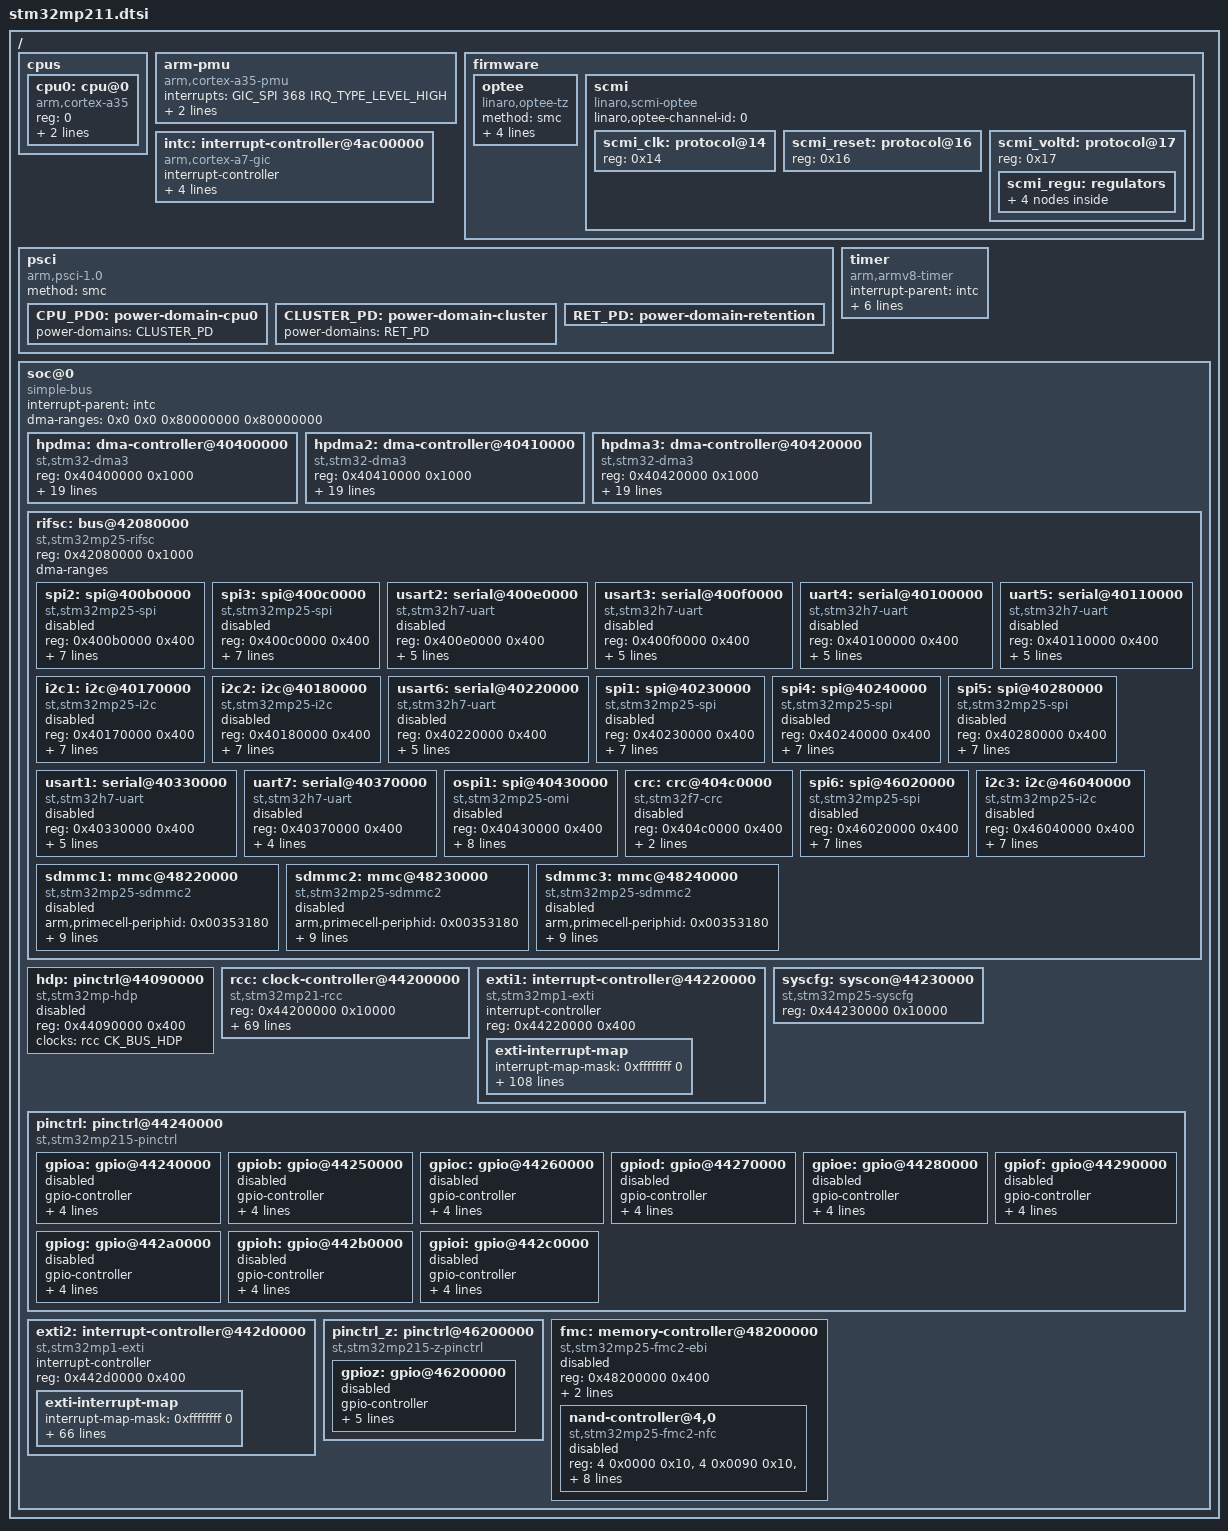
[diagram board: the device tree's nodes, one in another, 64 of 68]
// SPDX-License-Identifier: (GPL-2.0-only OR BSD-3-Clause)
/*
 * Copyright (C) STMicroelectronics 2024 - All Rights Reserved
 * Author: Alexandre Torgue <alexandre.torgue@foss.st.com> for STMicroelectronics.
 */
#include <dt-bindings/clock/st,stm32mp21-rcc.h>
#include <dt-bindings/interrupt-controller/arm-gic.h>
#include <dt-bindings/reset/st,stm32mp21-rcc.h>
#include <dt-bindings/regulator/st,stm32mp21-regulator.h>

/ {
	#address-cells = <2>;
	#size-cells = <2>;

	cpus {
		#address-cells = <1>;
		#size-cells = <0>;

		cpu0: cpu@0 {
			compatible = "arm,cortex-a35";
			device_type = "cpu";
			reg = <0>;
			enable-method = "psci";
			power-domains = <&CPU_PD0>;
			power-domain-names = "psci";
		};
	};

	arm-pmu {
		compatible = "arm,cortex-a35-pmu";
		interrupts = <GIC_SPI 368 IRQ_TYPE_LEVEL_HIGH>;
		interrupt-affinity = <&cpu0>;
		interrupt-parent = <&intc>;
	};

	firmware {
		optee {
			compatible = "linaro,optee-tz";
			method = "smc";
			interrupt-parent = <&intc>;
			interrupts = <GIC_PPI 15 (GIC_CPU_MASK_SIMPLE(1) | IRQ_TYPE_LEVEL_LOW)>;
			interrupt-controller;
			#interrupt-cells = <1>;
		};

		scmi: scmi {
			compatible = "linaro,scmi-optee";
			#address-cells = <1>;
			#size-cells = <0>;
			linaro,optee-channel-id = <0>;

			scmi_clk: protocol@14 {
				reg = <0x14>;
				#clock-cells = <1>;
			};

			scmi_reset: protocol@16 {
				reg = <0x16>;
				#reset-cells = <1>;
			};

			scmi_voltd: protocol@17 {
				reg = <0x17>;

				scmi_regu: regulators {
					#address-cells = <1>;
					#size-cells = <0>;

					scmi_vddio1: regulator@0 {
						reg = <VOLTD_SCMI_VDDIO1>;
						regulator-name = "vddio1";
					};
					scmi_vddio2: regulator@1 {
						reg = <VOLTD_SCMI_VDDIO2>;
						regulator-name = "vddio2";
					};
					scmi_vddio3: regulator@2 {
						reg = <VOLTD_SCMI_VDDIO3>;
						regulator-name = "vddio3";
					};
					scmi_vdda18adc: regulator@7 {
						reg = <VOLTD_SCMI_ADC>;
						regulator-name = "vdda18adc";
					};
				};
			};
		};
	};

	intc: interrupt-controller@4ac00000 {
		compatible = "arm,cortex-a7-gic";
		#interrupt-cells = <3>;
		interrupt-controller;
		reg = <0x0 0x4ac10000 0x0 0x1000>,
		      <0x0 0x4ac20000 0x0 0x2000>,
		      <0x0 0x4ac40000 0x0 0x2000>,
		      <0x0 0x4ac60000 0x0 0x2000>;
	};

	psci {
		compatible = "arm,psci-1.0";
		method = "smc";

		CPU_PD0: power-domain-cpu0 {
			#power-domain-cells = <0>;
			power-domains = <&CLUSTER_PD>;
		};

		CLUSTER_PD: power-domain-cluster {
			#power-domain-cells = <0>;
			power-domains = <&RET_PD>;
		};

		RET_PD: power-domain-retention {
			#power-domain-cells = <0>;
		};
	};

	timer {
		compatible = "arm,armv8-timer";
		interrupt-parent = <&intc>;
		interrupts = <GIC_PPI 13 (GIC_CPU_MASK_SIMPLE(1) | IRQ_TYPE_LEVEL_LOW)>,
			     <GIC_PPI 14 (GIC_CPU_MASK_SIMPLE(1) | IRQ_TYPE_LEVEL_LOW)>,
			     <GIC_PPI 11 (GIC_CPU_MASK_SIMPLE(1) | IRQ_TYPE_LEVEL_LOW)>,
			     <GIC_PPI 10 (GIC_CPU_MASK_SIMPLE(1) | IRQ_TYPE_LEVEL_LOW)>;
		arm,no-tick-in-suspend;
	};

	soc@0 {
		compatible = "simple-bus";
		#address-cells = <1>;
		#size-cells = <1>;
		interrupt-parent = <&intc>;
		ranges = <0x0 0x0 0x0 0x80000000>;
		dma-ranges = <0x0 0x0 0x80000000 0x80000000>;

		hpdma: dma-controller@40400000 {
			compatible = "st,stm32-dma3";
			reg = <0x40400000 0x1000>;
			interrupts = <GIC_SPI 31 IRQ_TYPE_LEVEL_HIGH>,
				     <GIC_SPI 32 IRQ_TYPE_LEVEL_HIGH>,
				     <GIC_SPI 33 IRQ_TYPE_LEVEL_HIGH>,
				     <GIC_SPI 34 IRQ_TYPE_LEVEL_HIGH>,
				     <GIC_SPI 35 IRQ_TYPE_LEVEL_HIGH>,
				     <GIC_SPI 36 IRQ_TYPE_LEVEL_HIGH>,
				     <GIC_SPI 37 IRQ_TYPE_LEVEL_HIGH>,
				     <GIC_SPI 38 IRQ_TYPE_LEVEL_HIGH>,
				     <GIC_SPI 39 IRQ_TYPE_LEVEL_HIGH>,
				     <GIC_SPI 40 IRQ_TYPE_LEVEL_HIGH>,
				     <GIC_SPI 41 IRQ_TYPE_LEVEL_HIGH>,
				     <GIC_SPI 42 IRQ_TYPE_LEVEL_HIGH>,
				     <GIC_SPI 43 IRQ_TYPE_LEVEL_HIGH>,
				     <GIC_SPI 44 IRQ_TYPE_LEVEL_HIGH>,
				     <GIC_SPI 45 IRQ_TYPE_LEVEL_HIGH>,
				     <GIC_SPI 46 IRQ_TYPE_LEVEL_HIGH>;
			clocks = <&scmi_clk CK_SCMI_HPDMA1>;
			#dma-cells = <3>;
			st,axi-max-burst-len = <16>;
			st,syscfg-arcr = <&syscfg 0x2050 0x1>;
		};

		hpdma2: dma-controller@40410000 {
			compatible = "st,stm32-dma3";
			reg = <0x40410000 0x1000>;
			interrupts = <GIC_SPI 47 IRQ_TYPE_LEVEL_HIGH>,
				     <GIC_SPI 48 IRQ_TYPE_LEVEL_HIGH>,
				     <GIC_SPI 49 IRQ_TYPE_LEVEL_HIGH>,
				     <GIC_SPI 50 IRQ_TYPE_LEVEL_HIGH>,
				     <GIC_SPI 51 IRQ_TYPE_LEVEL_HIGH>,
				     <GIC_SPI 52 IRQ_TYPE_LEVEL_HIGH>,
				     <GIC_SPI 53 IRQ_TYPE_LEVEL_HIGH>,
				     <GIC_SPI 54 IRQ_TYPE_LEVEL_HIGH>,
				     <GIC_SPI 55 IRQ_TYPE_LEVEL_HIGH>,
				     <GIC_SPI 56 IRQ_TYPE_LEVEL_HIGH>,
				     <GIC_SPI 57 IRQ_TYPE_LEVEL_HIGH>,
				     <GIC_SPI 58 IRQ_TYPE_LEVEL_HIGH>,
				     <GIC_SPI 59 IRQ_TYPE_LEVEL_HIGH>,
				     <GIC_SPI 60 IRQ_TYPE_LEVEL_HIGH>,
				     <GIC_SPI 61 IRQ_TYPE_LEVEL_HIGH>,
				     <GIC_SPI 62 IRQ_TYPE_LEVEL_HIGH>;
			clocks = <&scmi_clk CK_SCMI_HPDMA2>;
			#dma-cells = <3>;
			st,axi-max-burst-len = <16>;
			st,syscfg-arcr = <&syscfg 0x2050 0x2>;
		};

		hpdma3: dma-controller@40420000 {
			compatible = "st,stm32-dma3";
			reg = <0x40420000 0x1000>;
			interrupts = <GIC_SPI 63 IRQ_TYPE_LEVEL_HIGH>,
				     <GIC_SPI 64 IRQ_TYPE_LEVEL_HIGH>,
				     <GIC_SPI 65 IRQ_TYPE_LEVEL_HIGH>,
				     <GIC_SPI 66 IRQ_TYPE_LEVEL_HIGH>,
				     <GIC_SPI 67 IRQ_TYPE_LEVEL_HIGH>,
				     <GIC_SPI 68 IRQ_TYPE_LEVEL_HIGH>,
				     <GIC_SPI 69 IRQ_TYPE_LEVEL_HIGH>,
				     <GIC_SPI 70 IRQ_TYPE_LEVEL_HIGH>,
				     <GIC_SPI 71 IRQ_TYPE_LEVEL_HIGH>,
				     <GIC_SPI 72 IRQ_TYPE_LEVEL_HIGH>,
				     <GIC_SPI 73 IRQ_TYPE_LEVEL_HIGH>,
				     <GIC_SPI 74 IRQ_TYPE_LEVEL_HIGH>,
				     <GIC_SPI 75 IRQ_TYPE_LEVEL_HIGH>,
				     <GIC_SPI 76 IRQ_TYPE_LEVEL_HIGH>,
				     <GIC_SPI 77 IRQ_TYPE_LEVEL_HIGH>,
				     <GIC_SPI 78 IRQ_TYPE_LEVEL_HIGH>;
			clocks = <&scmi_clk CK_SCMI_HPDMA3>;
			#dma-cells = <3>;
			st,axi-max-burst-len = <16>;
			st,syscfg-arcr = <&syscfg 0x2050 0x4>;
		};

		rifsc: bus@42080000 {
			compatible = "st,stm32mp25-rifsc", "simple-bus";
			reg = <0x42080000 0x1000>;
			#address-cells = <1>;
			#size-cells = <1>;
			#access-controller-cells = <1>;
			ranges;
			dma-ranges;

			spi2: spi@400b0000 {
				#address-cells = <1>;
				#size-cells = <0>;
				compatible = "st,stm32mp25-spi";
				reg = <0x400b0000 0x400>;
				interrupts = <GIC_SPI 100 IRQ_TYPE_LEVEL_HIGH>;
				clocks = <&rcc CK_KER_SPI2>;
				resets = <&rcc SPI2_R>;
				dmas = <&hpdma 34 0x40 0x3012>,
				       <&hpdma 35 0x40 0x3021>;
				dma-names = "rx", "tx";
				access-controllers = <&rifsc 23>;
				power-domains = <&CLUSTER_PD>;
				status = "disabled";
			};

			spi3: spi@400c0000 {
				#address-cells = <1>;
				#size-cells = <0>;
				compatible = "st,stm32mp25-spi";
				reg = <0x400c0000 0x400>;
				interrupts = <GIC_SPI 112 IRQ_TYPE_LEVEL_HIGH>;
				clocks = <&rcc CK_KER_SPI3>;
				resets = <&rcc SPI3_R>;
				dmas = <&hpdma 36 0x40 0x3012>,
				       <&hpdma 37 0x40 0x3021>;
				dma-names = "rx", "tx";
				access-controllers = <&rifsc 24>;
				power-domains = <&CLUSTER_PD>;
				status = "disabled";
			};

			usart2: serial@400e0000 {
				compatible = "st,stm32h7-uart";
				reg = <0x400e0000 0x400>;
				interrupts = <GIC_SPI 102 IRQ_TYPE_LEVEL_HIGH>;
				clocks = <&rcc CK_KER_USART2>;
				dmas = <&hpdma 11 0x40 0x12>,
				       <&hpdma 12 0x40 0x3021>;
				dma-names = "rx", "tx";
				access-controllers = <&rifsc 32>;
				power-domains = <&CLUSTER_PD>;
				status = "disabled";
			};

			usart3: serial@400f0000 {
				compatible = "st,stm32h7-uart";
				reg = <0x400f0000 0x400>;
				interrupts = <GIC_SPI 103 IRQ_TYPE_LEVEL_HIGH>;
				clocks = <&rcc CK_KER_USART3>;
				dmas = <&hpdma 13 0x40 0x12>,
				       <&hpdma 14 0x40 0x3021>;
				dma-names = "rx", "tx";
				access-controllers = <&rifsc 33>;
				power-domains = <&CLUSTER_PD>;
				status = "disabled";
			};

			uart4: serial@40100000 {
				compatible = "st,stm32h7-uart";
				reg = <0x40100000 0x400>;
				interrupts = <GIC_SPI 113 IRQ_TYPE_LEVEL_HIGH>;
				clocks = <&rcc CK_KER_UART4>;
				dmas = <&hpdma 15 0x40 0x12>,
				       <&hpdma 16 0x40 0x3021>;
				dma-names = "rx", "tx";
				access-controllers = <&rifsc 34>;
				power-domains = <&CLUSTER_PD>;
				status = "disabled";
			};

			uart5: serial@40110000 {
				compatible = "st,stm32h7-uart";
				reg = <0x40110000 0x400>;
				interrupts = <GIC_SPI 114 IRQ_TYPE_LEVEL_HIGH>;
				clocks = <&rcc CK_KER_UART5>;
				dmas = <&hpdma 17 0x40 0x12>,
				       <&hpdma 18 0x40 0x3021>;
				dma-names = "rx", "tx";
				access-controllers = <&rifsc 35>;
				power-domains = <&CLUSTER_PD>;
				status = "disabled";
			};

			i2c1: i2c@40170000 {
				compatible = "st,stm32mp25-i2c";
				reg = <0x40170000 0x400>;
				interrupt-names = "event";
				interrupts = <GIC_SPI 95 IRQ_TYPE_LEVEL_HIGH>;
				clocks = <&rcc CK_KER_I2C1>;
				resets = <&rcc I2C1_R>;
				#address-cells = <1>;
				#size-cells = <0>;
				dmas = <&hpdma 23 0x40 0x3012>,
				       <&hpdma 24 0x40 0x3021>;
				dma-names = "rx", "tx";
				access-controllers = <&rifsc 41>;
				power-domains = <&CLUSTER_PD>;
				status = "disabled";
			};

			i2c2: i2c@40180000 {
				compatible = "st,stm32mp25-i2c";
				reg = <0x40180000 0x400>;
				interrupt-names = "event";
				interrupts = <GIC_SPI 97 IRQ_TYPE_LEVEL_HIGH>;
				clocks = <&rcc CK_KER_I2C2>;
				resets = <&rcc I2C2_R>;
				#address-cells = <1>;
				#size-cells = <0>;
				dmas = <&hpdma 26 0x40 0x3012>,
				       <&hpdma 27 0x40 0x3021>;
				dma-names = "rx", "tx";
				access-controllers = <&rifsc 42>;
				power-domains = <&CLUSTER_PD>;
				status = "disabled";
			};

			usart6: serial@40220000 {
				compatible = "st,stm32h7-uart";
				reg = <0x40220000 0x400>;
				interrupts = <GIC_SPI 123 IRQ_TYPE_LEVEL_HIGH>;
				clocks = <&rcc CK_KER_USART6>;
				dmas = <&hpdma 19 0x40 0x12>,
				       <&hpdma 20 0x40 0x3021>;
				dma-names = "rx", "tx";
				access-controllers = <&rifsc 36>;
				power-domains = <&CLUSTER_PD>;
				status = "disabled";
			};

			spi1: spi@40230000 {
				#address-cells = <1>;
				#size-cells = <0>;
				compatible = "st,stm32mp25-spi";
				reg = <0x40230000 0x400>;
				interrupts = <GIC_SPI 99 IRQ_TYPE_LEVEL_HIGH>;
				clocks = <&rcc CK_KER_SPI1>;
				resets = <&rcc SPI1_R>;
				dmas = <&hpdma 32 0x40 0x3012>,
				       <&hpdma 33 0x40 0x3021>;
				dma-names = "rx", "tx";
				access-controllers = <&rifsc 22>;
				power-domains = <&CLUSTER_PD>;
				status = "disabled";
			};

			spi4: spi@40240000 {
				#address-cells = <1>;
				#size-cells = <0>;
				compatible = "st,stm32mp25-spi";
				reg = <0x40240000 0x400>;
				interrupts = <GIC_SPI 137 IRQ_TYPE_LEVEL_HIGH>;
				clocks = <&rcc CK_KER_SPI4>;
				resets = <&rcc SPI4_R>;
				dmas = <&hpdma 38 0x40 0x3012>,
				       <&hpdma 39 0x40 0x3021>;
				dma-names = "rx", "tx";
				access-controllers = <&rifsc 25>;
				power-domains = <&CLUSTER_PD>;
				status = "disabled";
			};

			spi5: spi@40280000 {
				#address-cells = <1>;
				#size-cells = <0>;
				compatible = "st,stm32mp25-spi";
				reg = <0x40280000 0x400>;
				interrupts = <GIC_SPI 138 IRQ_TYPE_LEVEL_HIGH>;
				clocks = <&rcc CK_KER_SPI5>;
				resets = <&rcc SPI5_R>;
				dmas = <&hpdma 40 0x40 0x3012>,
				       <&hpdma 41 0x40 0x3021>;
				dma-names = "rx", "tx";
				access-controllers = <&rifsc 26>;
				power-domains = <&CLUSTER_PD>;
				status = "disabled";
			};

			usart1: serial@40330000 {
				compatible = "st,stm32h7-uart";
				reg = <0x40330000 0x400>;
				interrupts = <GIC_SPI 101 IRQ_TYPE_LEVEL_HIGH>;
				clocks = <&rcc CK_KER_USART1>;
				dmas = <&hpdma 9 0x40 0x12>,
				       <&hpdma 10 0x40 0x3021>;
				dma-names = "rx", "tx";
				access-controllers = <&rifsc 31>;
				power-domains = <&CLUSTER_PD>;
				status = "disabled";
			};

			uart7: serial@40370000 {
				compatible = "st,stm32h7-uart";
				reg = <0x40370000 0x400>;
				interrupts = <GIC_SPI 135 IRQ_TYPE_LEVEL_HIGH>;
				clocks = <&rcc CK_KER_UART7>;
				dmas = <&hpdma 21 0x40 0x12>,
				       <&hpdma 22 0x40 0x3021>;
				dma-names = "rx", "tx";
				access-controllers = <&rifsc 37>;
				status = "disabled";
			};

			ospi1: spi@40430000 {
				compatible = "st,stm32mp25-omi";
				reg = <0x40430000 0x400>;
				interrupts = <GIC_SPI 146 IRQ_TYPE_LEVEL_HIGH>;
				dmas = <&hpdma 2 0x62 0x00003121>,
				       <&hpdma 2 0x42 0x00003112>;
				dma-names = "tx", "rx";
				st,syscfg-dlyb = <&syscfg 0x1000>;
				clocks = <&scmi_clk CK_SCMI_OSPI1>;
				resets = <&scmi_reset RST_SCMI_OSPI1>, <&scmi_reset RST_SCMI_OSPI1DLL>;
				access-controllers = <&rifsc 74>;
				status = "disabled";
			};

			crc: crc@404c0000 {
				compatible = "st,stm32f7-crc";
				reg = <0x404c0000 0x400>;
				clocks = <&rcc CK_BUS_CRC>;
				access-controllers = <&rifsc 109>;
				status = "disabled";
			};

			spi6: spi@46020000 {
				#address-cells = <1>;
				#size-cells = <0>;
				compatible = "st,stm32mp25-spi";
				reg = <0x46020000 0x400>;
				interrupts = <GIC_SPI 139 IRQ_TYPE_LEVEL_HIGH>;
				clocks = <&rcc CK_KER_SPI6>;
				resets = <&rcc SPI6_R>;
				dmas = <&hpdma 42 0x40 0x3012>,
				       <&hpdma 43 0x40 0x3021>;
				dma-names = "rx", "tx";
				access-controllers = <&rifsc 27>;
				power-domains = <&CLUSTER_PD>;
				status = "disabled";
			};

			i2c3: i2c@46040000 {
				compatible = "st,stm32mp25-i2c";
				reg = <0x46040000 0x400>;
				interrupt-names = "event";
				interrupts = <GIC_SPI 137 IRQ_TYPE_LEVEL_HIGH>;
				clocks = <&rcc CK_KER_I2C3>;
				resets = <&rcc I2C3_R>;
				#address-cells = <1>;
				#size-cells = <0>;
				dmas = <&hpdma 29 0x40 0x3012>,
				       <&hpdma 30 0x40 0x3021>;
				dma-names = "rx", "tx";
				access-controllers = <&rifsc 43>;
				power-domains = <&CLUSTER_PD>;
				status = "disabled";
			};

			sdmmc1: mmc@48220000 {
				compatible = "st,stm32mp25-sdmmc2", "arm,pl18x", "arm,primecell";
				arm,primecell-periphid = <0x00353180>;
				reg = <0x48220000 0x400>, <0x44230400 0x8>;
				interrupts = <GIC_SPI 110 IRQ_TYPE_LEVEL_HIGH>;
				clocks = <&rcc CK_KER_SDMMC1>;
				clock-names = "apb_pclk";
				resets = <&rcc SDMMC1_R>;
				cap-sd-highspeed;
				cap-mmc-highspeed;
				max-frequency = <120000000>;
				access-controllers = <&rifsc 76>;
				st,syscfg-arcr = <&syscfg 0x40c 0x1>;
				status = "disabled";
			};

			sdmmc2: mmc@48230000 {
				compatible = "st,stm32mp25-sdmmc2", "arm,pl18x", "arm,primecell";
				arm,primecell-periphid = <0x00353180>;
				reg = <0x48230000 0x400>, <0x44230800 0x8>;
				interrupts = <GIC_SPI 169 IRQ_TYPE_LEVEL_HIGH>;
				clocks = <&rcc CK_KER_SDMMC2>;
				clock-names = "apb_pclk";
				resets = <&rcc SDMMC2_R>;
				cap-sd-highspeed;
				cap-mmc-highspeed;
				max-frequency = <120000000>;
				access-controllers = <&rifsc 77>;
				st,syscfg-arcr = <&syscfg 0x80c 0x1>;
				status = "disabled";
			};

			sdmmc3: mmc@48240000 {
				compatible = "st,stm32mp25-sdmmc2", "arm,pl18x", "arm,primecell";
				arm,primecell-periphid = <0x00353180>;
				reg = <0x48240000 0x400>, <0x44230c00 0x8>;
				interrupts = <GIC_SPI 179 IRQ_TYPE_LEVEL_HIGH>;
				clocks = <&rcc CK_KER_SDMMC3>;
				clock-names = "apb_pclk";
				resets = <&rcc SDMMC3_R>;
				cap-sd-highspeed;
				cap-mmc-highspeed;
				max-frequency = <120000000>;
				access-controllers = <&rifsc 78>;
				st,syscfg-arcr = <&syscfg 0xc0c 0x1>;
				status = "disabled";
			};
		};

		hdp: pinctrl@44090000 {
			compatible = "st,stm32mp-hdp";
			reg = <0x44090000 0x400>;
			clocks = <&rcc CK_BUS_HDP>;
			status = "disabled";
		};

		rcc: clock-controller@44200000 {
			compatible = "st,stm32mp21-rcc";
			reg = <0x44200000 0x10000>;
			#clock-cells = <1>;
			#reset-cells = <1>;
			clocks =
				<&scmi_clk CK_SCMI_HSE>,
				<&scmi_clk CK_SCMI_HSI>,
				<&scmi_clk CK_SCMI_MSI>,
				<&scmi_clk CK_SCMI_LSE>,
				<&scmi_clk CK_SCMI_LSI>,
				<&scmi_clk CK_SCMI_HSE_DIV2>,
				<&scmi_clk CK_SCMI_ICN_HS_MCU>,
				<&scmi_clk CK_SCMI_ICN_LS_MCU>,
				<&scmi_clk CK_SCMI_ICN_SDMMC>,
				<&scmi_clk CK_SCMI_ICN_DDR>,
				<&scmi_clk CK_SCMI_ICN_DISPLAY>,
				<&scmi_clk CK_SCMI_ICN_HSL>,
				<&scmi_clk CK_SCMI_ICN_NIC>,
				<&scmi_clk CK_SCMI_FLEXGEN_07>,
				<&scmi_clk CK_SCMI_FLEXGEN_08>,
				<&scmi_clk CK_SCMI_FLEXGEN_09>,
				<&scmi_clk CK_SCMI_FLEXGEN_10>,
				<&scmi_clk CK_SCMI_FLEXGEN_11>,
				<&scmi_clk CK_SCMI_FLEXGEN_12>,
				<&scmi_clk CK_SCMI_FLEXGEN_13>,
				<&scmi_clk CK_SCMI_FLEXGEN_14>,
				<&scmi_clk CK_SCMI_FLEXGEN_16>,
				<&scmi_clk CK_SCMI_FLEXGEN_17>,
				<&scmi_clk CK_SCMI_FLEXGEN_18>,
				<&scmi_clk CK_SCMI_FLEXGEN_19>,
				<&scmi_clk CK_SCMI_FLEXGEN_20>,
				<&scmi_clk CK_SCMI_FLEXGEN_21>,
				<&scmi_clk CK_SCMI_FLEXGEN_22>,
				<&scmi_clk CK_SCMI_FLEXGEN_23>,
				<&scmi_clk CK_SCMI_FLEXGEN_24>,
				<&scmi_clk CK_SCMI_FLEXGEN_25>,
				<&scmi_clk CK_SCMI_FLEXGEN_26>,
				<&scmi_clk CK_SCMI_FLEXGEN_27>,
				<&scmi_clk CK_SCMI_FLEXGEN_29>,
				<&scmi_clk CK_SCMI_FLEXGEN_30>,
				<&scmi_clk CK_SCMI_FLEXGEN_31>,
				<&scmi_clk CK_SCMI_FLEXGEN_33>,
				<&scmi_clk CK_SCMI_FLEXGEN_36>,
				<&scmi_clk CK_SCMI_FLEXGEN_37>,
				<&scmi_clk CK_SCMI_FLEXGEN_38>,
				<&scmi_clk CK_SCMI_FLEXGEN_39>,
				<&scmi_clk CK_SCMI_FLEXGEN_40>,
				<&scmi_clk CK_SCMI_FLEXGEN_41>,
				<&scmi_clk CK_SCMI_FLEXGEN_42>,
				<&scmi_clk CK_SCMI_FLEXGEN_43>,
				<&scmi_clk CK_SCMI_FLEXGEN_44>,
				<&scmi_clk CK_SCMI_FLEXGEN_45>,
				<&scmi_clk CK_SCMI_FLEXGEN_46>,
				<&scmi_clk CK_SCMI_FLEXGEN_47>,
				<&scmi_clk CK_SCMI_FLEXGEN_48>,
				<&scmi_clk CK_SCMI_FLEXGEN_50>,
				<&scmi_clk CK_SCMI_FLEXGEN_51>,
				<&scmi_clk CK_SCMI_FLEXGEN_52>,
				<&scmi_clk CK_SCMI_FLEXGEN_53>,
				<&scmi_clk CK_SCMI_FLEXGEN_54>,
				<&scmi_clk CK_SCMI_FLEXGEN_55>,
				<&scmi_clk CK_SCMI_FLEXGEN_56>,
				<&scmi_clk CK_SCMI_FLEXGEN_57>,
				<&scmi_clk CK_SCMI_FLEXGEN_58>,
				<&scmi_clk CK_SCMI_FLEXGEN_61>,
				<&scmi_clk CK_SCMI_FLEXGEN_62>,
				<&scmi_clk CK_SCMI_FLEXGEN_63>,
				<&scmi_clk CK_SCMI_ICN_APB1>,
				<&scmi_clk CK_SCMI_ICN_APB2>,
				<&scmi_clk CK_SCMI_ICN_APB3>,
				<&scmi_clk CK_SCMI_ICN_APB4>,
				<&scmi_clk CK_SCMI_ICN_APB5>,
				<&scmi_clk CK_SCMI_ICN_APBDBG>,
				<&scmi_clk CK_SCMI_TIMG1>,
				<&scmi_clk CK_SCMI_TIMG2>;
			access-controllers = <&rifsc 156>;
		};

		exti1: interrupt-controller@44220000 {
			compatible = "st,stm32mp1-exti";
			interrupt-controller;
			#interrupt-cells = <2>;
			#address-cells = <0>;
			reg = <0x44220000 0x400>;
			exti-interrupt-map {
				#address-cells = <0>;
				#interrupt-cells = <2>;
				interrupt-map-mask = <0xffffffff 0>;
				interrupt-map =
					<0  0 &intc 0 0 GIC_SPI 268 IRQ_TYPE_LEVEL_HIGH>,
					<1  0 &intc 0 0 GIC_SPI 269 IRQ_TYPE_LEVEL_HIGH>,
					<2  0 &intc 0 0 GIC_SPI 270 IRQ_TYPE_LEVEL_HIGH>,
					<3  0 &intc 0 0 GIC_SPI 271 IRQ_TYPE_LEVEL_HIGH>,
					<4  0 &intc 0 0 GIC_SPI 272 IRQ_TYPE_LEVEL_HIGH>,
					<5  0 &intc 0 0 GIC_SPI 273 IRQ_TYPE_LEVEL_HIGH>,
					<6  0 &intc 0 0 GIC_SPI 274 IRQ_TYPE_LEVEL_HIGH>,
					<7  0 &intc 0 0 GIC_SPI 275 IRQ_TYPE_LEVEL_HIGH>,
					<8  0 &intc 0 0 GIC_SPI 276 IRQ_TYPE_LEVEL_HIGH>,
					<9  0 &intc 0 0 GIC_SPI 277 IRQ_TYPE_LEVEL_HIGH>,
					<10 0 &intc 0 0 GIC_SPI 278 IRQ_TYPE_LEVEL_HIGH>,
					<11 0 &intc 0 0 GIC_SPI 279 IRQ_TYPE_LEVEL_HIGH>,
					<12 0 &intc 0 0 GIC_SPI 280 IRQ_TYPE_LEVEL_HIGH>,
					<13 0 &intc 0 0 GIC_SPI 281 IRQ_TYPE_LEVEL_HIGH>,
					<14 0 &intc 0 0 GIC_SPI 282 IRQ_TYPE_LEVEL_HIGH>,
					<15 0 &intc 0 0 GIC_SPI 283 IRQ_TYPE_LEVEL_HIGH>,
					<16 0 &intc 0 0 GIC_SPI 0   IRQ_TYPE_LEVEL_HIGH>,
					<17 0 &intc 0 0 GIC_SPI 1   IRQ_TYPE_LEVEL_HIGH>,
					<18 0 &intc 0 0 GIC_SPI 211 IRQ_TYPE_LEVEL_HIGH>,
					<19 0 &intc 0 0 GIC_SPI 210 IRQ_TYPE_LEVEL_HIGH>,
					<21 0 &intc 0 0 GIC_SPI 95  IRQ_TYPE_LEVEL_HIGH>,
					<22 0 &intc 0 0 GIC_SPI 97  IRQ_TYPE_LEVEL_HIGH>,
					<23 0 &intc 0 0 GIC_SPI 124 IRQ_TYPE_LEVEL_HIGH>,
					<26 0 &intc 0 0 GIC_SPI 101 IRQ_TYPE_LEVEL_HIGH>,
					<27 0 &intc 0 0 GIC_SPI 102 IRQ_TYPE_LEVEL_HIGH>,
					<28 0 &intc 0 0 GIC_SPI 103 IRQ_TYPE_LEVEL_HIGH>,
					<29 0 &intc 0 0 GIC_SPI 123 IRQ_TYPE_LEVEL_HIGH>,
					<30 0 &intc 0 0 GIC_SPI 113 IRQ_TYPE_LEVEL_HIGH>,
					<31 0 &intc 0 0 GIC_SPI 114 IRQ_TYPE_LEVEL_HIGH>,
					<32 0 &intc 0 0 GIC_SPI 135 IRQ_TYPE_LEVEL_HIGH>,
					<36 0 &intc 0 0 GIC_SPI 99  IRQ_TYPE_LEVEL_HIGH>,
					<37 0 &intc 0 0 GIC_SPI 100 IRQ_TYPE_LEVEL_HIGH>,
					<38 0 &intc 0 0 GIC_SPI 112 IRQ_TYPE_LEVEL_HIGH>,
					<39 0 &intc 0 0 GIC_SPI 137 IRQ_TYPE_LEVEL_HIGH>,
					<40 0 &intc 0 0 GIC_SPI 138 IRQ_TYPE_LEVEL_HIGH>,
					<41 0 &intc 0 0 GIC_SPI 139 IRQ_TYPE_LEVEL_HIGH>,
					<43 0 &intc 0 0 GIC_SPI 150 IRQ_TYPE_LEVEL_HIGH>,
					<44 0 &intc 0 0 GIC_SPI 158 IRQ_TYPE_LEVEL_HIGH>,
					<47 0 &intc 0 0 GIC_SPI 149 IRQ_TYPE_LEVEL_HIGH>,
					<48 0 &intc 0 0 GIC_SPI 180 IRQ_TYPE_LEVEL_HIGH>,
					<59 0 &intc 0 0 GIC_SPI 152 IRQ_TYPE_LEVEL_HIGH>,
					//	<59 0 &intc 0 0 GIC_SPI 153 IRQ_TYPE_LEVEL_HIGH>,
					<61 0 &intc 0 0 GIC_SPI 154 IRQ_TYPE_LEVEL_HIGH>,
					//	<61 0 &intc 0 0 GIC_SPI 155 IRQ_TYPE_LEVEL_HIGH>,
					<64 0 &intc 0 0 GIC_SPI 185 IRQ_TYPE_LEVEL_HIGH>,
					<67 0 &intc 0 0 GIC_SPI 9   IRQ_TYPE_LEVEL_HIGH>,
					<68 0 &intc 0 0 GIC_SPI 118 IRQ_TYPE_LEVEL_HIGH>,
					<70 0 &intc 0 0 GIC_SPI 121 IRQ_TYPE_LEVEL_HIGH>,
					<72 0 &intc 0 0 GIC_SPI 188 IRQ_TYPE_LEVEL_HIGH>,
					<73 0 &intc 0 0 GIC_SPI 172 IRQ_TYPE_LEVEL_HIGH>,
					<74 0 &intc 0 0 GIC_SPI 96  IRQ_TYPE_LEVEL_HIGH>,
					<75 0 &intc 0 0 GIC_SPI 98  IRQ_TYPE_LEVEL_HIGH>,
					<76 0 &intc 0 0 GIC_SPI 125 IRQ_TYPE_LEVEL_HIGH>,
					<77 0 &intc 0 0 GIC_SPI 205 IRQ_TYPE_LEVEL_HIGH>,
					<78 0 &intc 0 0 GIC_SPI 206 IRQ_TYPE_LEVEL_HIGH>,
					<79 0 &intc 0 0 GIC_SPI 207 IRQ_TYPE_LEVEL_HIGH>;
			};
		};

		syscfg: syscon@44230000 {
			compatible = "st,stm32mp25-syscfg", "syscon";
			reg = <0x44230000 0x10000>;
		};

		pinctrl: pinctrl@44240000 {
			#address-cells = <1>;
			#size-cells = <1>;
			compatible = "st,stm32mp215-pinctrl";
			ranges = <0 0x44240000 0x80400>;

			gpioa: gpio@44240000 {
				gpio-controller;
				#gpio-cells = <2>;
				interrupt-controller;
				#interrupt-cells = <2>;
				reg = <0x0 0x400>;
				clocks = <&scmi_clk CK_SCMI_GPIOA>;
				st,bank-name = "GPIOA";
				status = "disabled";
			};

			gpiob: gpio@44250000 {
				gpio-controller;
				#gpio-cells = <2>;
				interrupt-controller;
				#interrupt-cells = <2>;
				reg = <0x10000 0x400>;
				clocks = <&scmi_clk CK_SCMI_GPIOB>;
				st,bank-name = "GPIOB";
				status = "disabled";
			};

			gpioc: gpio@44260000 {
				gpio-controller;
				#gpio-cells = <2>;
				interrupt-controller;
				#interrupt-cells = <2>;
				reg = <0x20000 0x400>;
				clocks = <&scmi_clk CK_SCMI_GPIOC>;
				st,bank-name = "GPIOC";
				status = "disabled";
			};

			gpiod: gpio@44270000 {
				gpio-controller;
				#gpio-cells = <2>;
				interrupt-controller;
				#interrupt-cells = <2>;
				reg = <0x30000 0x400>;
				clocks = <&scmi_clk CK_SCMI_GPIOD>;
				st,bank-name = "GPIOD";
				status = "disabled";
			};

			gpioe: gpio@44280000 {
				gpio-controller;
				#gpio-cells = <2>;
				interrupt-controller;
				#interrupt-cells = <2>;
				reg = <0x40000 0x400>;
				clocks = <&scmi_clk CK_SCMI_GPIOE>;
				st,bank-name = "GPIOE";
				status = "disabled";
			};

			gpiof: gpio@44290000 {
				gpio-controller;
				#gpio-cells = <2>;
				interrupt-controller;
				#interrupt-cells = <2>;
				reg = <0x50000 0x400>;
				clocks = <&scmi_clk CK_SCMI_GPIOF>;
				st,bank-name = "GPIOF";
				status = "disabled";
			};

			gpiog: gpio@442a0000 {
				gpio-controller;
				#gpio-cells = <2>;
				interrupt-controller;
				#interrupt-cells = <2>;
				reg = <0x60000 0x400>;
				clocks = <&scmi_clk CK_SCMI_GPIOG>;
				st,bank-name = "GPIOG";
				status = "disabled";
			};

			gpioh: gpio@442b0000 {
				gpio-controller;
				#gpio-cells = <2>;
				interrupt-controller;
				#interrupt-cells = <2>;
				reg = <0x70000 0x400>;
				clocks = <&scmi_clk CK_SCMI_GPIOH>;
				st,bank-name = "GPIOH";
				status = "disabled";
			};

			gpioi: gpio@442c0000 {
				gpio-controller;
				#gpio-cells = <2>;
				interrupt-controller;
				#interrupt-cells = <2>;
				reg = <0x80000 0x400>;
				clocks = <&scmi_clk CK_SCMI_GPIOI>;
				st,bank-name = "GPIOI";
				status = "disabled";
			};
		};

		exti2: interrupt-controller@442d0000 {
			compatible = "st,stm32mp1-exti";
			interrupt-controller;
			#interrupt-cells = <2>;
			#address-cells = <0>;
			reg = <0x442d0000 0x400>;

			exti-interrupt-map {
				#address-cells = <0>;
				#interrupt-cells = <2>;
				interrupt-map-mask = <0xffffffff 0>;
				interrupt-map =
					<0  0 &intc 0 0 GIC_SPI 15  IRQ_TYPE_LEVEL_HIGH>,
					<1  0 &intc 0 0 GIC_SPI 16  IRQ_TYPE_LEVEL_HIGH>,
					<2  0 &intc 0 0 GIC_SPI 17  IRQ_TYPE_LEVEL_HIGH>,
					<3  0 &intc 0 0 GIC_SPI 18  IRQ_TYPE_LEVEL_HIGH>,
					<4  0 &intc 0 0 GIC_SPI 19  IRQ_TYPE_LEVEL_HIGH>,
					<5  0 &intc 0 0 GIC_SPI 20  IRQ_TYPE_LEVEL_HIGH>,
					<6  0 &intc 0 0 GIC_SPI 21  IRQ_TYPE_LEVEL_HIGH>,
					<7  0 &intc 0 0 GIC_SPI 22  IRQ_TYPE_LEVEL_HIGH>,
					<8  0 &intc 0 0 GIC_SPI 23  IRQ_TYPE_LEVEL_HIGH>,
					<9  0 &intc 0 0 GIC_SPI 24  IRQ_TYPE_LEVEL_HIGH>,
					<10 0 &intc 0 0 GIC_SPI 25  IRQ_TYPE_LEVEL_HIGH>,
					<11 0 &intc 0 0 GIC_SPI 26  IRQ_TYPE_LEVEL_HIGH>,
					<12 0 &intc 0 0 GIC_SPI 27  IRQ_TYPE_LEVEL_HIGH>,
					<13 0 &intc 0 0 GIC_SPI 28  IRQ_TYPE_LEVEL_HIGH>,
					<14 0 &intc 0 0 GIC_SPI 29  IRQ_TYPE_LEVEL_HIGH>,
					<15 0 &intc 0 0 GIC_SPI 30  IRQ_TYPE_LEVEL_HIGH>,
					<16 0 &intc 0 0 GIC_SPI 10  IRQ_TYPE_LEVEL_HIGH>,
					<17 0 &intc 0 0 GIC_SPI 11  IRQ_TYPE_LEVEL_HIGH>,
					<21 0 &intc 0 0 GIC_SPI 12  IRQ_TYPE_LEVEL_HIGH>,
					<22 0 &intc 0 0 GIC_SPI 13  IRQ_TYPE_LEVEL_HIGH>,
					<26 0 &intc 0 0 GIC_SPI 136 IRQ_TYPE_LEVEL_HIGH>,
					<29 0 &intc 0 0 GIC_SPI 181 IRQ_TYPE_LEVEL_HIGH>,
					<30 0 &intc 0 0 GIC_SPI 182 IRQ_TYPE_LEVEL_HIGH>,
					<31 0 &intc 0 0 GIC_SPI 183 IRQ_TYPE_LEVEL_HIGH>,
					<35 0 &intc 0 0 GIC_SPI 5   IRQ_TYPE_LEVEL_HIGH>,
					<36 0 &intc 0 0 GIC_SPI 4   IRQ_TYPE_LEVEL_HIGH>,
					<37 0 &intc 0 0 GIC_SPI 6   IRQ_TYPE_LEVEL_HIGH>,
					<39 0 &intc 0 0 GIC_SPI 2   IRQ_TYPE_LEVEL_HIGH>,
					<40 0 &intc 0 0 GIC_SPI 3   IRQ_TYPE_LEVEL_HIGH>,
					<49 0 &intc 0 0 GIC_SPI 201 IRQ_TYPE_LEVEL_HIGH>,
					<51 0 &intc 0 0 GIC_SPI 202 IRQ_TYPE_LEVEL_HIGH>,
					<52 0 &intc 0 0 GIC_SPI 203 IRQ_TYPE_LEVEL_HIGH>,
					<53 0 &intc 0 0 GIC_SPI 204 IRQ_TYPE_LEVEL_HIGH>;
			};
		};

		pinctrl_z: pinctrl@46200000 {
			#address-cells = <1>;
			#size-cells = <1>;
			compatible = "st,stm32mp215-z-pinctrl";
			ranges = <0 0x46200000 0x400>;

			gpioz: gpio@46200000 {
				gpio-controller;
				#gpio-cells = <2>;
				interrupt-controller;
				#interrupt-cells = <2>;
				reg = <0 0x400>;
				clocks = <&scmi_clk CK_SCMI_GPIOZ>;
				st,bank-name = "GPIOZ";
				st,bank-ioport = <11>;
				status = "disabled";
			};
		};

		fmc: memory-controller@48200000 {
			compatible = "st,stm32mp25-fmc2-ebi";
			reg = <0x48200000 0x400>;
			ranges = <0 0 0x70000000 0x04000000>, /* EBI CS 1 */
				 <1 0 0x74000000 0x04000000>, /* EBI CS 2 */
				 <2 0 0x78000000 0x04000000>, /* EBI CS 3 */
				 <3 0 0x7c000000 0x04000000>, /* EBI CS 4 */
				 <4 0 0x48810000 0x00001000>; /* NAND */
			#address-cells = <2>;
			#size-cells = <1>;
			clocks = <&scmi_clk CK_SCMI_FMC>;
			resets = <&scmi_reset RST_SCMI_FMC>;
			status = "disabled";

			nand-controller@4,0 {
				compatible = "st,stm32mp25-fmc2-nfc";
				reg = <4 0x0000 0x10>,
				      <4 0x0090 0x10>,
				      <4 0x00a0 0x10>,
				      <4 0x0400 0x10>,
				      <4 0x0490 0x10>,
				      <4 0x04a0 0x10>,
				      <4 0x0800 0x10>,
				      <4 0x0890 0x10>,
				      <4 0x08a0 0x10>,
				      <4 0x0c00 0x10>,
				      <4 0x0c90 0x10>,
				      <4 0x0ca0 0x10>;
				#address-cells = <1>;
				#size-cells = <0>;
				interrupts = <GIC_SPI 109 IRQ_TYPE_LEVEL_HIGH>;
				dmas = <&hpdma 0 0x62 0x00003121>,
				       <&hpdma 0 0x62 0x00003112>,
				       <&hpdma 1 0x42 0x00013113>;
				dma-names = "tx", "rx", "ecc";
				status = "disabled";
			};
		};
	};
};
